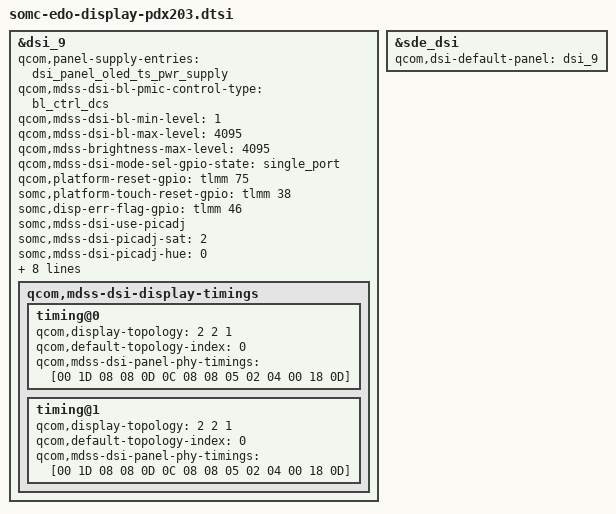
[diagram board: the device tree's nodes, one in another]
#include "dsi-panel-souxp00_a-amb650wh07-uhd.dtsi"

&dsi_9 {
	qcom,panel-supply-entries = <&dsi_panel_oled_ts_pwr_supply>;
	qcom,mdss-dsi-bl-pmic-control-type = "bl_ctrl_dcs";
	qcom,mdss-dsi-bl-min-level = <1>;
	qcom,mdss-dsi-bl-max-level = <4095>;
	qcom,mdss-brightness-max-level = <4095>;
	qcom,mdss-dsi-mode-sel-gpio-state = "single_port";

	qcom,platform-reset-gpio = <&tlmm 75 0>;
	somc,platform-touch-reset-gpio = <&tlmm 38 0>;
	somc,disp-err-flag-gpio = <&tlmm 46 0>;

	somc,mdss-dsi-use-picadj;
	somc,mdss-dsi-picadj-sat = <2>;
	somc,mdss-dsi-picadj-hue = <0>;
	somc,mdss-dsi-picadj-val = <0>;
	somc,mdss-dsi-picadj-cont = <0>;

	somc,mdss-dsi-pcc-enable;
	somc,mdss-dsi-pcc-force-cal;
	somc,panel-colormgr-pcc-prof-avail;
	somc,mdss-dsi-pcc-table-size = <6>;
	somc,mdss-dsi-pcc-table = <
		0x00 0x01 0x00 0x03 0x00 0x03 0x6a72 0x7116 0x8000
		0x00 0x02 0x00 0x03 0x00 0x03 0x8000 0x718c 0x7768
		0x00 0x03 0x00 0x03 0x00 0x03 0x795c 0x7448 0x8000
		0x00 0x04 0x00 0x03 0x00 0x03 0x64b4 0x6978 0x8000
		0xFF 0x00 0x0E 0x38 0x0C 0x2F 0x8000 0x8000 0x8000>;

	qcom,mdss-dsi-display-timings {
		timing@0 {
			qcom,display-topology = <2 2 1>;
			qcom,default-topology-index = <0>;
			qcom,mdss-dsi-panel-phy-timings = [00 1D 08 08 0D 0C 08 08 05 02 04 00 18 0D];
		};
		timing@1 {
			qcom,display-topology = <2 2 1>;
			qcom,default-topology-index = <0>;
			qcom,mdss-dsi-panel-phy-timings = [00 1D 08 08 0D 0C 08 08 05 02 04 00 18 0D];
		};
	};
};

&sde_dsi {
	qcom,dsi-default-panel = <&dsi_9>;
};

